# CM_WKUP register map
Vendor: Texas Instruments
Peripheral module from a debugger description file (folder am437x).
Registers are 32-bit, access per field, no defined reset value unless marked. A register's access mark holds for its fields unless they carry their own. Offsets are as the file gives them; lines under a group give offsets from that group; [hi:lo] are bit positions; {n}, {i} and the like mark numbered series; 'fields as' and 'values as' point back to an identical list; <NAME> marks a mode.

## CM_WKUP
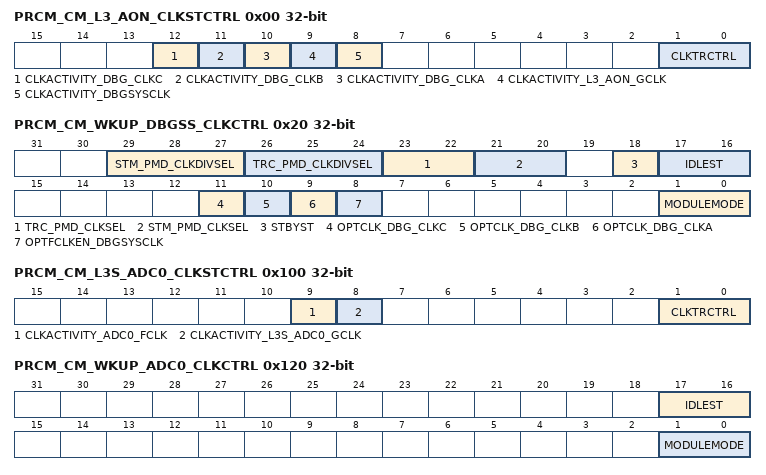
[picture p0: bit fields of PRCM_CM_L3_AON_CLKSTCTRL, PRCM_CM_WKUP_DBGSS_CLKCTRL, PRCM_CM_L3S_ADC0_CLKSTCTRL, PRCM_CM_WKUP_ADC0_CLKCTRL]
0x00 PRCM_CM_L3_AON_CLKSTCTRL — This register enables the domain power state transition. It controls the SW supervised clock domain state transition between ON-ACTIVE and ON-INACTIVE states. It also hold one status bit per clock input of the domain.
  [12] CLKACTIVITY_DBG_CLKC ro — This field indicates the state of the Debugss CLKC clock in the domain.
  [11] CLKACTIVITY_DBG_CLKB ro — This field indicates the state of the Debugss CLKB clock in the domain.
  [10] CLKACTIVITY_DBG_CLKA ro — This field indicates the state of the Debugss CLKA clock in the domain.
  [9] CLKACTIVITY_L3_AON_GCLK ro — This field indicates the state of the L3_AON clock in the domain.
    1=en_2_0x1 (Corresponding clock is active); 0=en_1_0x0 (Corresponding clock is gated)
  [8] CLKACTIVITY_DBGSYSCLK ro — This field indicates the state of the Debugss sysclk clock in the domain.
    values as CLKACTIVITY_L3_AON_GCLK
  [1:0] CLKTRCTRL rw — Controls the clock state transition of the l3 AON clock domain.
    3=en_4_0x3 (Reserved); 2=en_3_0x2 (SW_WKUP: Start a software forced wake-up transition on the domain.); 1=en_2_0x1 (SW_SLEEP: Start a software forced sleep transition on the domain.); 0=en_1_0x0 (NO_SLEEP: Sleep transition cannot be initiated. Wakeup transition may however occur.)
0x20 PRCM_CM_WKUP_DBGSS_CLKCTRL — This register manages the DEBUGSS clocks. [warm reset insensitive]
  [29:27] STM_PMD_CLKDIVSEL rw — STM Trace clock divider control
    4=en_3_0x4 (Divide by 4); 2=en_2_0x2 (Divide by 2); 0=en_1_0x0 (Divide by 1)
  [26:24] TRC_PMD_CLKDIVSEL rw — TPIU trace clock divider control
    values as STM_PMD_CLKDIVSEL
  [23:22] TRC_PMD_CLKSEL rw — TPIU Trace clock select
    3=en_4_0x3 (Selects CLKC as TPIU trace clock); 2=en_3_0x2 (Selects CLKB as TPIU trace clock); 1=en_2_0x1 (Selects CLKA as TPIU trace clock); 0=en_1_0x0 (Selects DGBSYSCLK as TPIU trace clock)
  [21:20] STM_PMD_CLKSEL rw — STM trace clock select
    3=en_4_0x3 (Selects CLKC as STM trace clock); 2=en_3_0x2 (Selects CLKB as STM trace clock); 1=en_2_0x1 (Selects CLKA as STM trace clock); 0=en_1_0x0 (Selects DGBSYSCLK as STM trace clock)
  [18] STBYST ro — Module standby status.
    1=en_2_0x1 (Module is in standby); 0=en_1_0x0 (Module is functional (not in standby))
  [17:16] IDLEST ro — Module idle status.
    3=en_4_0x3 (Module is disabled and cannot be accessed); 2=en_3_0x2 (Module is in Idle mode (only OCP part). It is functional if using separate functional clock); 1=en_2_0x1 (Module is performing transition: wakeup, or sleep, or sleep abortion); 0=en_1_0x0 (Module is fully functional, including OCP)
  [11] OPTCLK_DBG_CLKC rw — Controls Optional Functional Clock CLKC
    1=en_2_0x1 (Enable optional clock DEBUG_CLKC); 0=en_1_0x0 (Disable optional clock DEBUG_CLKC)
  [10] OPTCLK_DBG_CLKB rw — Controls Optional Functional Clock CLKB
    1=en_2_0x1 (Enable optional clock DEBUG_CLKB); 0=en_1_0x0 (Disable optional clock DEBUG_CLKB)
  [9] OPTCLK_DBG_CLKA rw — Optional functional clock control
    1=en_2_0x1 (Enable optional clock DEBUG_CLKA); 0=en_1_0x0 (Disable optional clock DEBUG_CLKA)
  [8] OPTFCLKEN_DBGSYSCLK rw — Optional functional clock control.
    1=en_2_0x1 (Optional functional clock is enabled); 0=en_1_0x0 (Optional functional clock is disabled)
  [1:0] MODULEMODE rw — Control the way mandatory clocks are managed.
    3=en_4_0x3 (Reserved); 2=en_3_0x2 (Module is explicitly enabled. Interface clock (if not used for functions) may be gated according to the clock domain state. Functional clocks are guarantied to stay present. As long as in this configuration, power domain sleep transition cannot happen.); 1=en_2_0x1 (Reserved); 0=en_1_0x0 (Module is disable by SW. Any OCP access to module results in an error, except if resulting from a module wakeup (asynchronous wakeup).)
0x100 PRCM_CM_L3S_ADC0_CLKSTCTRL — This register enables the domain power state transition. It controls the SW supervised clock domain state transition between ON-ACTIVE and ON-INACTIVE states. It also hold one status bit per clock input of the domain.
  [9] CLKACTIVITY_ADC0_FCLK ro — This field indicates the state of the ADC0 FCLK clock in the domain.
    values as PRCM_CM_L3_AON_CLKSTCTRL.CLKACTIVITY_L3_AON_GCLK
  [8] CLKACTIVITY_L3S_ADC0_GCLK ro — This field indicates the state of the L3S_ADC0 clock in the domain.
    values as PRCM_CM_L3_AON_CLKSTCTRL.CLKACTIVITY_L3_AON_GCLK
  [1:0] CLKTRCTRL rw — Controls the clock state transition of the always on clock domain.
    values as PRCM_CM_L3_AON_CLKSTCTRL.CLKTRCTRL
0x120 PRCM_CM_WKUP_ADC0_CLKCTRL — This register manages the ADC0 clocks.
  [17:16] IDLEST ro — Module idle status.
    values as PRCM_CM_WKUP_DBGSS_CLKCTRL.IDLEST
  [1:0] MODULEMODE rw — Control the way mandatory clocks are managed.
    values as PRCM_CM_WKUP_DBGSS_CLKCTRL.MODULEMODE
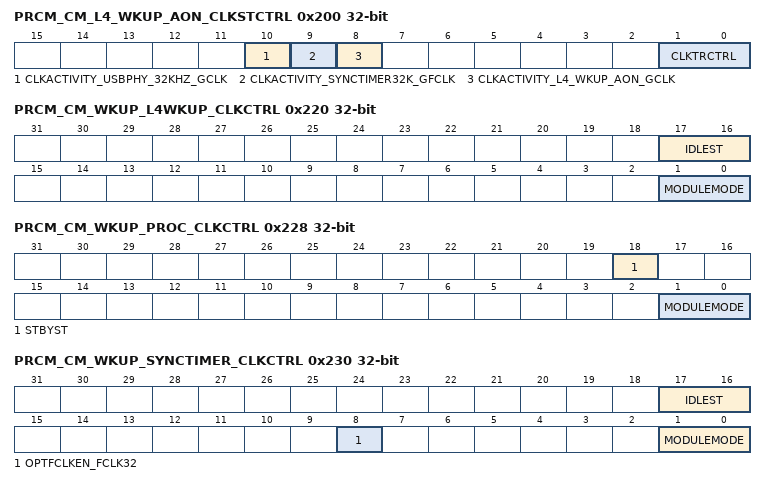
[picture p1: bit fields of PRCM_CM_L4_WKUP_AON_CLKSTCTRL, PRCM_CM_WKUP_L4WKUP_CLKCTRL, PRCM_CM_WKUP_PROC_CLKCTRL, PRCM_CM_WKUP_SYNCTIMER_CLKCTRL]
0x200 PRCM_CM_L4_WKUP_AON_CLKSTCTRL ro — This register enables the domain power state transition. It controls the SW supervised clock domain state transition between ON-ACTIVE and ON-INACTIVE states. It also hold one status bit per clock input of the domain.
  [10] CLKACTIVITY_USBPHY_32KHZ_GCLK — This field indicates the state of the USBPHY 32KHZ clock in the domain.
    values as PRCM_CM_L3_AON_CLKSTCTRL.CLKACTIVITY_L3_AON_GCLK
  [9] CLKACTIVITY_SYNCTIMER32K_GFCLK — This field indicates the state of the SYNCTIMER clock in the domain.
    values as PRCM_CM_L3_AON_CLKSTCTRL.CLKACTIVITY_L3_AON_GCLK
  [8] CLKACTIVITY_L4_WKUP_AON_GCLK — This field indicates the state of the L4_WKUP clock in the domain.
    values as PRCM_CM_L3_AON_CLKSTCTRL.CLKACTIVITY_L3_AON_GCLK
  [1:0] CLKTRCTRL — Controls the clock state transition of the always on L4 clock domain.
0x220 PRCM_CM_WKUP_L4WKUP_CLKCTRL ro — This register manages the L4WKUP clocks.
  [17:16] IDLEST — Module idle status.
    values as PRCM_CM_WKUP_DBGSS_CLKCTRL.IDLEST
  [1:0] MODULEMODE — Control the way mandatory clocks are managed.
0x228 PRCM_CM_WKUP_PROC_CLKCTRL ro — This register manages the WKUP M3 clocks.
  [18] STBYST — Module standby status.
    values as PRCM_CM_WKUP_DBGSS_CLKCTRL.STBYST
  [1:0] MODULEMODE — Control the way mandatory clocks are managed.
0x230 PRCM_CM_WKUP_SYNCTIMER_CLKCTRL — This register manages the SYNCTIMER clocks.
  [17:16] IDLEST ro — Module idle status.
    values as PRCM_CM_WKUP_DBGSS_CLKCTRL.IDLEST
  [8] OPTFCLKEN_FCLK32 rw — Optional functional clock control.
    values as PRCM_CM_WKUP_DBGSS_CLKCTRL.OPTFCLKEN_DBGSYSCLK
  [1:0] MODULEMODE rw — Control the way mandatory clocks are managed.
    values as PRCM_CM_WKUP_DBGSS_CLKCTRL.MODULEMODE
0x238 PRCM_CM_WKUP_CLKDIV32K_CLKCTRL — This register manages the CLKDIV32K clocks.
  [8] OPTFCLKEN_FCLK rw — Optional functional clock control.
    values as PRCM_CM_WKUP_DBGSS_CLKCTRL.OPTFCLKEN_DBGSYSCLK
0x240 PRCM_CM_WKUP_USBPHY0_CLKCTRL — This register manages the USBPHY0 32KHz clocks.
  [8] OPTFCLKEN_CLK32K rw — Optional functional clock control.
    values as PRCM_CM_WKUP_DBGSS_CLKCTRL.OPTFCLKEN_DBGSYSCLK
0x248 PRCM_CM_WKUP_USBPHY1_CLKCTRL — This register manages the USBPHY1 32KHz clocks.
  fields as PRCM_CM_WKUP_USBPHY0_CLKCTRL
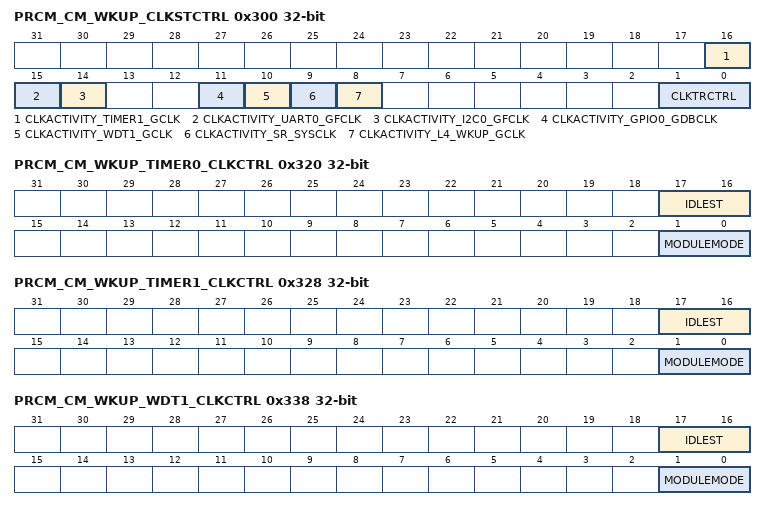
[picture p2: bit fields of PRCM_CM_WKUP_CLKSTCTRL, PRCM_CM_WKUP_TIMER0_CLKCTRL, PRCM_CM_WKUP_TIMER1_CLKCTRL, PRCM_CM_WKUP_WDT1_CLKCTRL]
0x300 PRCM_CM_WKUP_CLKSTCTRL — This register enables the domain power state transition. It controls the SW supervised clock domain state transition between ON-ACTIVE and ON-INACTIVE states. It also hold one status bit per clock input of the domain.
  [16] CLKACTIVITY_TIMER1_GCLK ro — This field indicates the state of the TIMER1 clock in the domain.
    values as PRCM_CM_L3_AON_CLKSTCTRL.CLKACTIVITY_L3_AON_GCLK
  [15] CLKACTIVITY_UART0_GFCLK ro — This field indicates the state of the UART0 clock in the domain.
    values as PRCM_CM_L3_AON_CLKSTCTRL.CLKACTIVITY_L3_AON_GCLK
  [14] CLKACTIVITY_I2C0_GFCLK ro — This field indicates the state of the I2C0 clock in the domain.
    values as PRCM_CM_L3_AON_CLKSTCTRL.CLKACTIVITY_L3_AON_GCLK
  [11] CLKACTIVITY_GPIO0_GDBCLK ro — This field indicates the state of the WKUPGPIO_DBGICLK clock in the domain.
    values as PRCM_CM_L3_AON_CLKSTCTRL.CLKACTIVITY_L3_AON_GCLK
  [10] CLKACTIVITY_WDT1_GCLK ro — This field indicates the state of the WDT1_GCLK clock in the domain.
    values as PRCM_CM_L3_AON_CLKSTCTRL.CLKACTIVITY_L3_AON_GCLK
  [9] CLKACTIVITY_SR_SYSCLK ro — This field indicates the state of the SMARTREFLEX SYSCLK clock in the domain.
    values as PRCM_CM_L3_AON_CLKSTCTRL.CLKACTIVITY_L3_AON_GCLK
  [8] CLKACTIVITY_L4_WKUP_GCLK ro — This field indicates the state of the L4_WKUP clock in the domain.
    values as PRCM_CM_L3_AON_CLKSTCTRL.CLKACTIVITY_L3_AON_GCLK
  [1:0] CLKTRCTRL rw — Controls the clock state transition of the always on clock domain.
    values as PRCM_CM_L3_AON_CLKSTCTRL.CLKTRCTRL
0x320 PRCM_CM_WKUP_TIMER0_CLKCTRL — This register manages the TIMER0 clocks.
  fields as PRCM_CM_WKUP_ADC0_CLKCTRL
0x328 PRCM_CM_WKUP_TIMER1_CLKCTRL — This register manages the TIMER1 clocks.
  fields as PRCM_CM_WKUP_ADC0_CLKCTRL
0x338 PRCM_CM_WKUP_WDT1_CLKCTRL — This register manages the WDT1 clocks.
  fields as PRCM_CM_WKUP_ADC0_CLKCTRL
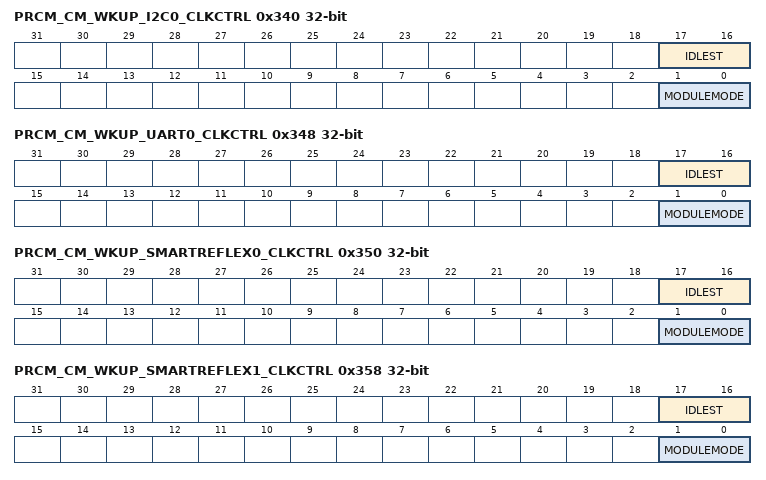
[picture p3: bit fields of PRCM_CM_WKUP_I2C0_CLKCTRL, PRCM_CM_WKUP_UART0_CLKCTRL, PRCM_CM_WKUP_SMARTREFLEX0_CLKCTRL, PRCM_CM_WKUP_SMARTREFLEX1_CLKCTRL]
0x340 PRCM_CM_WKUP_I2C0_CLKCTRL — This register manages the I2C0 clocks.
  fields as PRCM_CM_WKUP_ADC0_CLKCTRL
0x348 PRCM_CM_WKUP_UART0_CLKCTRL — This register manages the UART0 clocks.
  fields as PRCM_CM_WKUP_ADC0_CLKCTRL
0x350 PRCM_CM_WKUP_SMARTREFLEX0_CLKCTRL — This register manages the SmartReflex0 clocks.
  fields as PRCM_CM_WKUP_ADC0_CLKCTRL
0x358 PRCM_CM_WKUP_SMARTREFLEX1_CLKCTRL — This register manages the SmartReflex1 clocks.
  fields as PRCM_CM_WKUP_ADC0_CLKCTRL
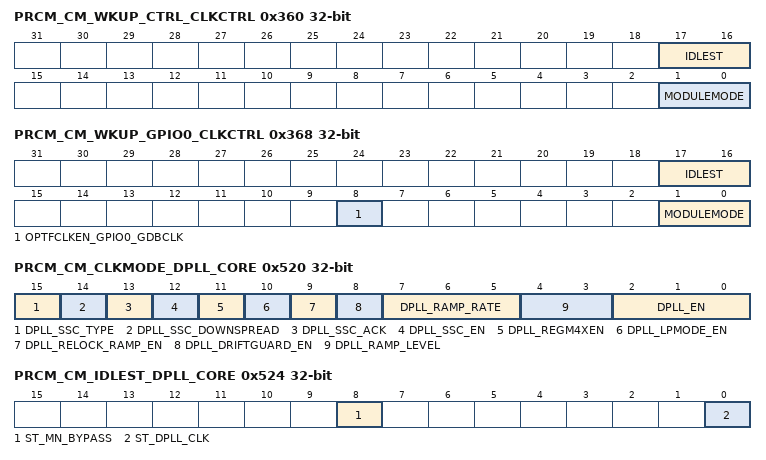
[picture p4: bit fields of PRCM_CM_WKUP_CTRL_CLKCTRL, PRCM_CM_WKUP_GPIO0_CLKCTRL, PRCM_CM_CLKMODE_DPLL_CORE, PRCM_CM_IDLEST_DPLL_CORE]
0x360 PRCM_CM_WKUP_CTRL_CLKCTRL — This register manages the Control Module clocks.
  fields as PRCM_CM_WKUP_ADC0_CLKCTRL
0x368 PRCM_CM_WKUP_GPIO0_CLKCTRL — This register manages the GPIO0 clocks.
  [17:16] IDLEST ro — Module idle status.
    values as PRCM_CM_WKUP_DBGSS_CLKCTRL.IDLEST
  [8] OPTFCLKEN_GPIO0_GDBCLK rw — Optional functional clock control.
    values as PRCM_CM_WKUP_DBGSS_CLKCTRL.OPTFCLKEN_DBGSYSCLK
  [1:0] MODULEMODE rw — Control the way mandatory clocks are managed.
    values as PRCM_CM_WKUP_DBGSS_CLKCTRL.MODULEMODE
0x520 PRCM_CM_CLKMODE_DPLL_CORE — This register allows controlling the DPLL modes.
  [15] DPLL_SSC_TYPE rw — Select between Triangular and SquareWave Spread Spectrum Clocking
    1=en_2_0x1 (Square Wave Spread Spectrum Clocking is selected (only available under proper licensing agreement)); 0=en_1_0x0 (Triangular Spread Spectrum Clocking is selected)
  [14] DPLL_SSC_DOWNSPREAD rw — Control if only low frequency spread is required
    1=en_2_0x1 (When SSC is enabled, clock frequency is spread only on the lower side of the programmed frequency); 0=en_1_0x0 (When SSC is enabled, clock frequency is spread on both sides of the programmed frequency)
  [13] DPLL_SSC_ACK ro — Acknowledgement from the DPLL regarding start and stop of Spread Spectrum Clocking feature
    1=en_2_0x1 (SSC has been turned on on PLL o/ps); 0=en_1_0x0 (SSC has been turned off on PLL o/ps)
  [12] DPLL_SSC_EN rw — Enable or disable Spread Spectrum Clocking
    1=en_2_0x1 (SSC enabled); 0=en_1_0x0 (SSC disabled)
  [11] DPLL_REGM4XEN ro — Enable the REGM4XEN mode of the DPLL. [[br]]Please check the DPLL documentation to check when this mode can be enabled.
    0=en_1_0x0 (REGM4XEN mode of the DPLL is disabled)
  [10] DPLL_LPMODE_EN rw — Set the DPLL in Low Power mode. [[br]]Check the DPLL documentation to see when this can be enabled.
    1=en_2_0x1 (Low power mode of the DPLL is enabled); 0=en_1_0x0 (Low power mode of the DPLL is disabled)
  [9] DPLL_RELOCK_RAMP_EN rw — If enabled, the clock ramping feature is used applied during the lock process, as well as the relock process. [[br]]If disabled, the clock ramping feature is used only during the first lock.
  [8] DPLL_DRIFTGUARD_EN rw — This bit allows to enable or disable the automatic recalibration feature of the DPLL. [[br]]The DPLL will automatically start a recalibration process upon assertion of the DPLL's RECAL flag if this bit is set.
    1=en_2_0x1 (DRIFTGUARD feature is enabled); 0=en_1_0x0 (DRIFTGUARD feature is disabled)
  [7:5] DPLL_RAMP_RATE rw — Selects the time in terms of DPLL REFCLKs spent at each stage of the clock ramping process
    7=en_8_0x7 (512 REFCLKs); 6=en_7_0x6 (128 REFCLKs); 5=en_6_0x5 (64 REFCLKs); 4=en_5_0x4 (32 REFCLKs); 3=en_4_0x3 (16 REFCLKs); 2=en_3_0x2 (8 REFCLKs); 1=en_2_0x1 (4 REFCLKs); 0=en_1_0x0 (2 REFCLKs)
  [4:3] DPLL_RAMP_LEVEL rw — The DPLL provides an output clock frequency ramping feature when switching from bypass clock to normal clock during lock and re-lock. [[br]]The frequency ramping will happen in a maximum of 4 steps in frequency before the DPLL's frequency lock indicator is asserted. [[br]]This register is used to enable/disable the DPLL ramping feature. [[br]]If enabled, it is also used to select the algorithm used for clock ramping
    3=en_4_0x3 (Reserved); 2=en_3_0x2 (CLKOUT => Bypass clk -> Fout/4 -> Fout/2 -> Fout/1.5 -> Fout CLKOUTX2 => Bypass clk -> Foutx2/4 -> Foutx2/2 -> Foutx2/1.5 -> Foutx2); 1=en_2_0x1 (CLKOUT => Bypass clk -> Fout/8 -> Fout/4 -> Fout/2 -> Fout CLKOUTX2 => Bypass clk -> Foutx2/8 -> Foutx2/4 -> Foutx2/2 -> Foutx2); 0=en_1_0x0 (CLKOUT => No ramping CLKOUTX2 => No ramping)
  [2:0] DPLL_EN rw — DPLL control. [[br]]Upon Warm Reset, the PRCM DPLL control state machine updates this register to reflect MN Bypass mode.
    7=en_8_0x7 (Enables the DPLL in Lock mode); 6=en_7_0x6 (Put the DPLL in Idle Bypass Fast Relock mode.); 5=en_6_0x5 (Put the DPLL in Idle Bypass Low Power mode.); 4=en_5_0x4 (Put the DPLL in MN Bypass mode. The DPLL_MULT register bits are reset to 0 automatically by putting the DPLL in this mode.); {v}=en_{v+1}_{0x0+v} (Reserved) (v=0..3)
0x524 PRCM_CM_IDLEST_DPLL_CORE ro — This register allows monitoring the master clock activity. This register is read only and automatically updated. [warm reset insensitive]
  [8] ST_MN_BYPASS — DPLL MN_BYPASS status
    1=en_2_0x1 (DPLL is in MN_Bypass); 0=en_1_0x0 (DPLL is not in MN_Bypass)
  [0] ST_DPLL_CLK — DPLL clock activity
    1=en_2_0x1 (DPLL is LOCKED); 0=en_1_0x0 (DPLL is either in bypass mode or in stop mode.)
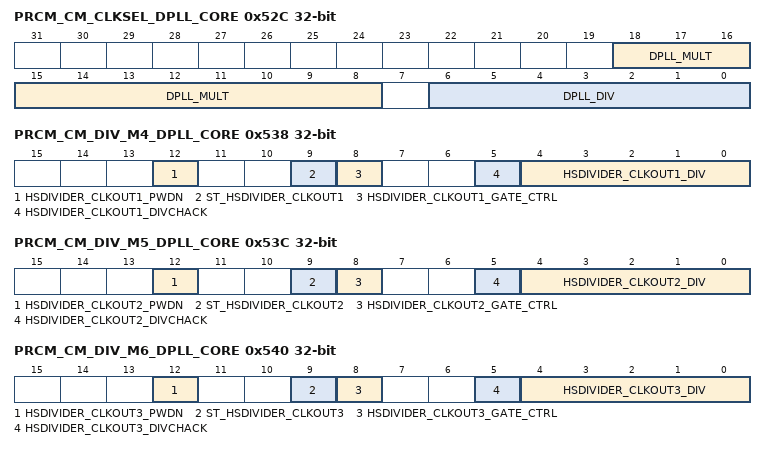
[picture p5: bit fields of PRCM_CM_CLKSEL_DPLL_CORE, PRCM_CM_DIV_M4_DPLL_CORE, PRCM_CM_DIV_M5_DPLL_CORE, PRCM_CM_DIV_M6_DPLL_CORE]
0x52C PRCM_CM_CLKSEL_DPLL_CORE — This register provides controls over the DPLL.
  [18:8] DPLL_MULT rw — DPLL multiplier factor (2 to 2047). [[br]]This register is automatically cleared to 0 when the DPLL_EN field in the *CLKMODE_DPLL* register is set to select MN Bypass mode. [[br]](equal to input M of DPLL[[br]] M=2 to [[br]]2047 => DPLL multiplies by M)
    1=en_2_0x1 (Reserved); 0=en_1_0x0 (Reserved)
  [6:0] DPLL_DIV rw — DPLL divider factor (0 to 127) (equal to input N of DPLL[[br]] actual division factor is N+1).
0x538 PRCM_CM_DIV_M4_DPLL_CORE — This register provides controls over the CLKOUT1 o/p of the HSDIVIDER.
  [12] HSDIVIDER_CLKOUT1_PWDN rw — Power down for HSDIVIDER M4 divider and hence CLKOUT1 output
    1=en_2_0x1 (M4 divider is powered down); 0=en_1_0x0 (M4 divider active)
  [9] ST_HSDIVIDER_CLKOUT1 ro — HSDIVIDER CLKOUT1 status
    1=en_2_0x1 (The clock output is enabled); 0=en_1_0x0 (The clock output is gated)
  [8] HSDIVIDER_CLKOUT1_GATE_CTRL rw — Control gating of HSDIVIDER CLKOUT1
    1=en_2_0x1 (Force this clock to stay enabled even if there is no request); 0=en_1_0x0 (Automatically gate this clock when there is no dependency for it)
  [5] HSDIVIDER_CLKOUT1_DIVCHACK ro — Toggle on this status bit after changing HSDIVIDER_CLKOUT1_DIV indicates that the change in divider value has taken effect
  [4:0] HSDIVIDER_CLKOUT1_DIV rw — DPLL post-divider factor, M4, for internal clock generation. [[br]]Divide values from 1 to 31.
    0=en_1_0x0 (Reserved)
0x53C PRCM_CM_DIV_M5_DPLL_CORE — This register provides controls over the CLKOUT2 o/p of the HSDIVIDER.
  [12] HSDIVIDER_CLKOUT2_PWDN rw — PPower down for HSDIVIDER M5 divider and hence CLKOUT2 output
    1=en_2_0x1 (M5 divider is powered down); 0=en_1_0x0 (M5 divider is ACTIVE)
  [9] ST_HSDIVIDER_CLKOUT2 ro — HSDIVIDER CLKOUT2 status
    values as PRCM_CM_DIV_M4_DPLL_CORE.ST_HSDIVIDER_CLKOUT1
  [8] HSDIVIDER_CLKOUT2_GATE_CTRL rw — Control gating of HSDIVIDER CLKOUT2
    values as PRCM_CM_DIV_M4_DPLL_CORE.HSDIVIDER_CLKOUT1_GATE_CTRL
  [5] HSDIVIDER_CLKOUT2_DIVCHACK ro — Toggle on this status bit after changing HSDIVIDER_CLKOUT2_DIV indicates that the change in divider value has taken effect
  [4:0] HSDIVIDER_CLKOUT2_DIV rw — DPLL post-divider factor, M5, for internal clock generation. [[br]]Divide values from 1 to 31.
    0=en_1_0x0 (Reserved)
0x540 PRCM_CM_DIV_M6_DPLL_CORE — This register provides controls over the CLKOUT3 o/p of the HSDIVIDER.
  [12] HSDIVIDER_CLKOUT3_PWDN rw — Power down for HSDIVIDER M6 divider and hence CLKOUT3 output
    1=en_2_0x1 (M6 divider is powered down); 0=en_1_0x0 (M6 divider is ACTIVE)
  [9] ST_HSDIVIDER_CLKOUT3 ro — HSDIVIDER CLKOUT3 status
    values as PRCM_CM_DIV_M4_DPLL_CORE.ST_HSDIVIDER_CLKOUT1
  [8] HSDIVIDER_CLKOUT3_GATE_CTRL rw — Control gating of HSDIVIDER CLKOUT3
    values as PRCM_CM_DIV_M4_DPLL_CORE.HSDIVIDER_CLKOUT1_GATE_CTRL
  [5] HSDIVIDER_CLKOUT3_DIVCHACK ro — Toggle on this status bit after changing HSDIVIDER_CLKOUT3_DIV indicates that the change in divider value has taken effect
  [4:0] HSDIVIDER_CLKOUT3_DIV rw — DPLL post-divider factor, M6, for internal clock generation. [[br]]Divide values from 1 to 31.
    0=en_1_0x0 (Reserved)
0x548 PRCM_CM_SSC_DELTAMSTEP_DPLL_CORE — Control the DeltaMStep parameter for Spread Spectrum Clocking technique DeltaMStep is split into fractional and integer part. [warm reset insensitive]
  [19:0] DELTAMSTEP rw — Fractional setting for DeltaMStep parameter
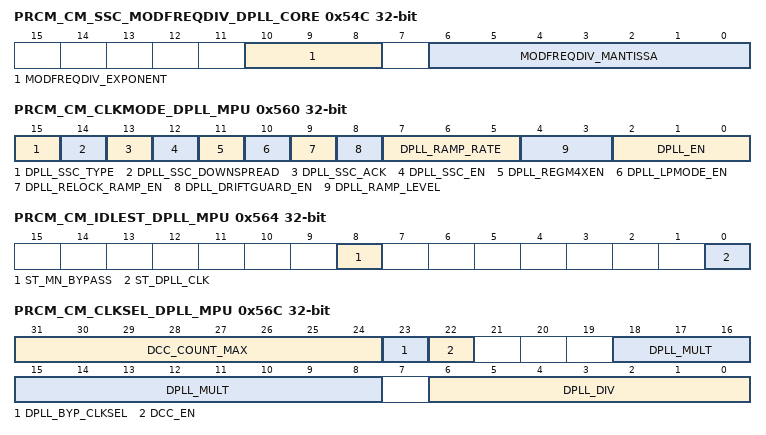
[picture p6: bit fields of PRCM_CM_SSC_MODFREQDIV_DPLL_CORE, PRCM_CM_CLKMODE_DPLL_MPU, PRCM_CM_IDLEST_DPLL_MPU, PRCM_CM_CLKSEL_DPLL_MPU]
0x54C PRCM_CM_SSC_MODFREQDIV_DPLL_CORE — Control the Modulation Frequency (Fm) for Spread Spectrum Clocking technique by defining it as a ratio of DPLL_REFCLK/4 Fm = [DPLL_REFCLK/4]/MODFREQDIV MODFREQDIV = MODFREQDIV_MANTISSA * 2^MODFREQDIV_EXPONENT [warm reset insensitive]
  [10:8] MODFREQDIV_EXPONENT rw — Set the Exponent component of MODFREQDIV factor
  [6:0] MODFREQDIV_MANTISSA rw — Set the Mantissa component of MODFREQDIV factor
0x560 PRCM_CM_CLKMODE_DPLL_MPU — This register allows controlling the DPLL modes.
  fields as PRCM_CM_CLKMODE_DPLL_CORE
0x564 PRCM_CM_IDLEST_DPLL_MPU ro — This register allows monitoring the master clock activity. This register is read only and automatically updated.[warm reset insensitive]
  fields as PRCM_CM_IDLEST_DPLL_CORE
0x56C PRCM_CM_CLKSEL_DPLL_MPU — This register provides controls over the DPLL.
  [31:24] DCC_COUNT_MAX rw — The value "NbCycles" set in this field determines the duration of the clock ramp step during which output frequency is Fdpll/(2*M2). [[br]]The duration is computed as 32 x NbCycles of WKUP-L4 clock cycles (SYSCLK/~26MHz). [[br]]Duration should be > 1.5us to allow enough time for DCC to lock. [[br]]This bit-field is only relevant when DCC_EN=1.
  [23] DPLL_BYP_CLKSEL rw — Selects CLKINP or CLKINPULOW as Bypass Clock
    1=en_2_0x1 (Selects CLKINPULOW as Bypass Clock); 0=en_1_0x0 (Selects CLKINP Clock as BYPASS Clock)
  [22] DCC_EN rw — Enable or disable Duty Cycle Correction. [[br]]Must be enabled only for frequency > 1GHz. [[br]]When enabled, the CLKOUTHIF output of the DPLL is used after duty cycle correction instead of CLKOUT. [[br]]M3 divider is hard-wired to 1 so the lock frequency Fdpll is directly provided to MPU.
    1=en_2_0x1 (DCC enabled); 0=en_1_0x0 (DCC disabled)
  [18:8] DPLL_MULT rw — DPLL multiplier factor (2 to 2047). [[br]]This register is automatically cleared to 0 when the DPLL_EN field in the *CLKMODE_DPLL* register is set to select MN Bypass mode. [[br]](equal to input M of DPLL[[br]] M=2 to [[br]]2047 => DPLL multiplies by M).
    1=en_2_0x1 (1 : Reserved); 0=en_1_0x0 (0 : Reserved)
  [6:0] DPLL_DIV rw — DPLL divider factor (0 to 127) (equal to input N of DPLL[[br]] actual division factor is N+1).
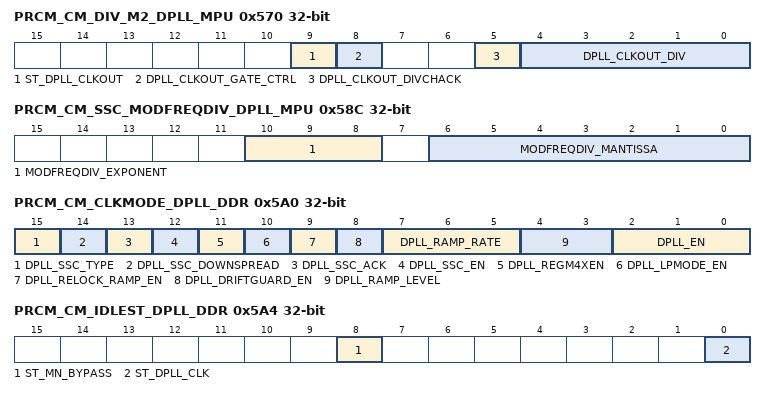
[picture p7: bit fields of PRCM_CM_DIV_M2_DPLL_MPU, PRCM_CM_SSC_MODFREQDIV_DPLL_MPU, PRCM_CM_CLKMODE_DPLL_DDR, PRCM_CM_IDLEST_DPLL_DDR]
0x570 PRCM_CM_DIV_M2_DPLL_MPU — This register provides controls over the M2 divider of the DPLL.
  [9] ST_DPLL_CLKOUT ro — DPLL CLKOUT status
    values as PRCM_CM_DIV_M4_DPLL_CORE.ST_HSDIVIDER_CLKOUT1
  [8] DPLL_CLKOUT_GATE_CTRL rw — Control gating of DPLL CLKOUT
    values as PRCM_CM_DIV_M4_DPLL_CORE.HSDIVIDER_CLKOUT1_GATE_CTRL
  [5] DPLL_CLKOUT_DIVCHACK ro — Toggle on this status bit after changing DPLL_CLKOUT_DIV indicates that the change in divider value has taken effect
  [4:0] DPLL_CLKOUT_DIV rw — DPLL M2 post-divider factor (1 to 31).
    0=en_1_0x0 (Reserved)
0x588 PRCM_CM_SSC_DELTAMSTEP_DPLL_MPU — Control the DeltaMStep parameter for Spread Spectrum Clocking technique DeltaMStep is split into fractional and integer part. [warm reset insensitive]
  [19:0] DELTAMSTEP rw — Fractional setting for DeltaMStep parameter
0x58C PRCM_CM_SSC_MODFREQDIV_DPLL_MPU — Control the Modulation Frequency (Fm) for Spread Spectrum Clocking technique by defining it as a ratio of DPLL_REFCLK/4 Fm = [DPLL_REFCLK/4]/MODFREQDIV MODFREQDIV = MODFREQDIV_MANTISSA * 2^MODFREQDIV_EXPONENT [warm reset insensitive]
  fields as PRCM_CM_SSC_MODFREQDIV_DPLL_CORE
0x5A0 PRCM_CM_CLKMODE_DPLL_DDR — This register allows controlling the DPLL modes.
  fields as PRCM_CM_CLKMODE_DPLL_CORE
0x5A4 PRCM_CM_IDLEST_DPLL_DDR ro — This register allows monitoring the master clock activity. This register is read only and automatically updated. [warm reset insensitive]
  fields as PRCM_CM_IDLEST_DPLL_CORE
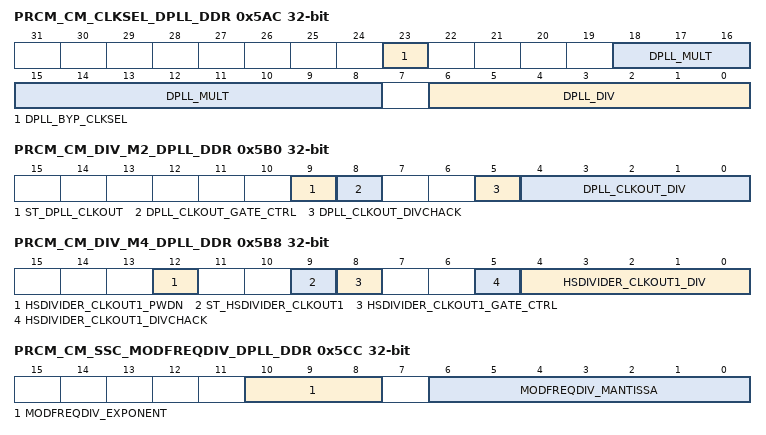
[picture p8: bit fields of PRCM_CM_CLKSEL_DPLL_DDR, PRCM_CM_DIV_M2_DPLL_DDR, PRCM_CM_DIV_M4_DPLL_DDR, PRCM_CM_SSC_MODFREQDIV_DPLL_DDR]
0x5AC PRCM_CM_CLKSEL_DPLL_DDR — This register provides controls over the DPLL.
  [23] DPLL_BYP_CLKSEL rw — Select CLKINP orr CLKINPULOW as bypass clock
    values as PRCM_CM_CLKSEL_DPLL_MPU.DPLL_BYP_CLKSEL
  [18:8] DPLL_MULT rw — DPLL multiplier factor (2 to 2047). [[br]]This register is automatically cleared to 0 when the DPLL_EN field in the *CLKMODE_DPLL* register is set to select MN Bypass mode. [[br]](equal to input M of DPLL[[br]] M=2 to [[br]]2047 => DPLL multiplies by M).
    1=en_2_0x1 (1 : Reserved); 0=en_1_0x0 (0 : Reserved)
  [6:0] DPLL_DIV rw — DPLL divider factor (0 to 127) (equal to input N of DPLL[[br]] actual division factor is N+1).
0x5B0 PRCM_CM_DIV_M2_DPLL_DDR — This register provides controls over the M2 divider of the DPLL.
  fields as PRCM_CM_DIV_M2_DPLL_MPU
0x5B8 PRCM_CM_DIV_M4_DPLL_DDR — This register provides controls over the CLKOUT1 o/p of the DDR PLL HSDIVIDER.
  fields as PRCM_CM_DIV_M4_DPLL_CORE
0x5C8 PRCM_CM_SSC_DELTAMSTEP_DPLL_DDR — Control the DeltaMStep parameter for Spread Spectrum Clocking technique DeltaMStep is split into fractional and integer part. [warm reset insensitive]
  [19:0] DELTAMSTEP rw — Fractional setting for DeltaMStep parameter
0x5CC PRCM_CM_SSC_MODFREQDIV_DPLL_DDR — Control the Modulation Frequency (Fm) for Spread Spectrum Clocking technique by defining it as a ratio of DPLL_REFCLK/4 Fm = [DPLL_REFCLK/4]/MODFREQDIV MODFREQDIV = MODFREQDIV_MANTISSA * 2^MODFREQDIV_EXPONENT [warm reset insensitive]
  fields as PRCM_CM_SSC_MODFREQDIV_DPLL_CORE
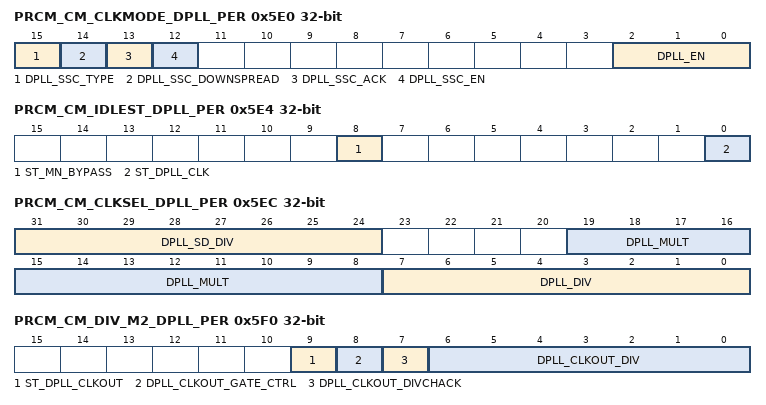
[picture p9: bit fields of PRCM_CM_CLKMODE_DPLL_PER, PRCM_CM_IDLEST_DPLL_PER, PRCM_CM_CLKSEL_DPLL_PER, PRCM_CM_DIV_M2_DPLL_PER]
0x5E0 PRCM_CM_CLKMODE_DPLL_PER — This register allows controlling the DPLL modes.
  [15] DPLL_SSC_TYPE rw — Select between Triangular and SquareWave Spread Spectrum Clocking
    values as PRCM_CM_CLKMODE_DPLL_CORE.DPLL_SSC_TYPE
  [14] DPLL_SSC_DOWNSPREAD rw — Control if only low frequency spread is required
    values as PRCM_CM_CLKMODE_DPLL_CORE.DPLL_SSC_DOWNSPREAD
  [13] DPLL_SSC_ACK ro — Acknowledgement from the DPLL regarding start and stop of Spread Spectrum Clocking feature
    values as PRCM_CM_CLKMODE_DPLL_CORE.DPLL_SSC_ACK
  [12] DPLL_SSC_EN rw — Enable or disable Spread Spectrum Clocking
    1=en_2_0x1 (SSC enabled); 0=en_1_0x0 (SSC disabled)
  [2:0] DPLL_EN rw — DPLL control. [[br]]Upon Warm Reset, the PRCM DPLL control state machine updates this register to reflect DPLL Low Power Stop mode.
    7=en_8_0x7 (Enables the DPLL in Lock mode); 6=en_7_0x6 (Reserved); 5=en_6_0x5 (Put the DPLL in Idle Bypass Low Power mode.); 4=en_5_0x4 (Put the DPLL in MN Bypass mode. The DPLL_MULT register bits are reset to 0 automatically by putting the DPLL in this mode.); 3=en_4_0x3 (Reserved); 2=en_3_0x2 (Reserved2); 1=en_2_0x1 (Reserved); 0=en_1_0x0 (Reserved)
0x5E4 PRCM_CM_IDLEST_DPLL_PER ro — This register allows monitoring the master clock activity. This register is read only and automatically updated. [warm reset insensitive]
  fields as PRCM_CM_IDLEST_DPLL_CORE
0x5EC PRCM_CM_CLKSEL_DPLL_PER — This register provides controls over the DPLL.
  [31:24] DPLL_SD_DIV rw — Sigma-Delta divider select ([[br]]2-255). [[br]]This factor must be set by s/w to ensure optimum jitter performance. [[br]]DPLL_SD_DIV = CEILING ([DPLL_MULT/(DPLL_DIV+1)] * CLKINP / 250), where CLKINP is the input clock of the DPLL in MHz). [[br]]Must be set with M and N factors, and must not be changed once DPLL is locked.
    1=en_2_0x1 (Reserved); 0=en_1_0x0 (Reserved)
  [19:8] DPLL_MULT rw — DPLL multiplier factor (2 to 4095). [[br]]This register is automatically cleared to 0 when the DPLL_EN field in the *CLKMODE_DPLL* register is set to select MN Bypass mode. [[br]](equal to input M of DPLL[[br]] M=2 to [[br]]4095 => DPLL multiplies by M).
    1=en_2_0x1 (1 : Reserved); 0=en_1_0x0 (0 : Reserved)
  [7:0] DPLL_DIV rw — DPLL divider factor (0 to 255) (equal to input N of DPLL[[br]] actual division factor is N+1).
0x5F0 PRCM_CM_DIV_M2_DPLL_PER — This register provides controls over the M2 divider of the DPLL.
  [9] ST_DPLL_CLKOUT ro — DPLL CLKOUT status
    values as PRCM_CM_DIV_M4_DPLL_CORE.ST_HSDIVIDER_CLKOUT1
  [8] DPLL_CLKOUT_GATE_CTRL rw — Control gating of DPLL CLKOUT
    values as PRCM_CM_DIV_M4_DPLL_CORE.HSDIVIDER_CLKOUT1_GATE_CTRL
  [7] DPLL_CLKOUT_DIVCHACK ro — Toggle on this status bit after changing DPLL_CLKOUT_DIV indicates that the change in divider value has taken effect
  [6:0] DPLL_CLKOUT_DIV rw — DPLL M2 post-divider factor (1 to 31).
    0=en_1_0x0 (Reserved)
0x604 PRCM_CM_CLKSEL2_DPLL_PER — This register provides DPLL fractional multiplier factor control and BandWidth Control for PER DPLL.
  [17:0] DPLL_MULT_FRAC rw — DPLL fractional multiplier factor. [[br]]Setting to 0 keeps DPLL in integer mode. [[br]]This field should be used only for DEBUG purpose.
0x608 PRCM_CM_SSC_DELTAMSTEP_DPLL_PER — Control the DeltaMStep parameter for Spread Spectrum Clocking technique DeltaMStep is split into fractional and integer part. [warm reset insensitive]
  [19:0] DELTAMSTEP rw — Fractional setting for DeltaMStep parameter
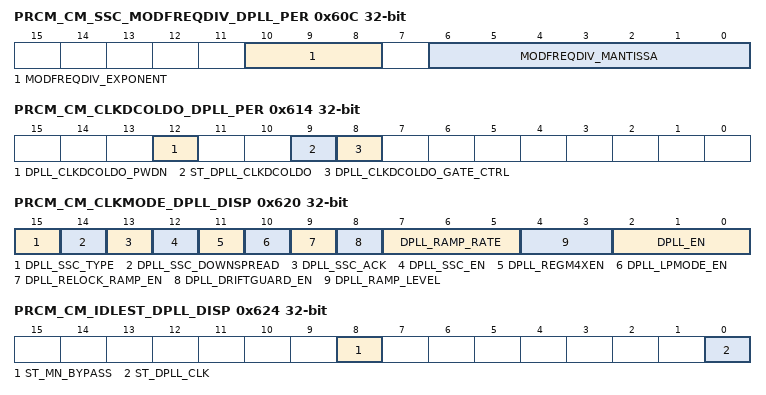
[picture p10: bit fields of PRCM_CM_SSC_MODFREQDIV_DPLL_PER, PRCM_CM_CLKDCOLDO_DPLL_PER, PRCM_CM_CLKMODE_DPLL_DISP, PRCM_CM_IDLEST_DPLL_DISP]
0x60C PRCM_CM_SSC_MODFREQDIV_DPLL_PER — Control the Modulation Frequency (Fm) for Spread Spectrum Clocking technique by defining it as a ratio of DPLL_REFCLK/4 Fm = [DPLL_REFCLK/4]/MODFREQDIV MODFREQDIV = MODFREQDIV_MANTISSA * 2^MODFREQDIV_EXPONENT [warm reset insensitive]
  fields as PRCM_CM_SSC_MODFREQDIV_DPLL_CORE
0x614 PRCM_CM_CLKDCOLDO_DPLL_PER — This register provides controls over the CLKDCOLDO output of the DPLL.
  [12] DPLL_CLKDCOLDO_PWDN rw — Software control for PWRDN on DCOLDO O/P
    1=en_2_0x1 (DCOLDO O/P is PWRDN); 0=en_1_0x0 (DCOLDO O/P is ACTIVE)
  [9] ST_DPLL_CLKDCOLDO ro — DPLL CLKDCOLDO status
    values as PRCM_CM_DIV_M4_DPLL_CORE.ST_HSDIVIDER_CLKOUT1
  [8] DPLL_CLKDCOLDO_GATE_CTRL rw — Control gating of DPLL CLKDCOLDO
    values as PRCM_CM_DIV_M4_DPLL_CORE.HSDIVIDER_CLKOUT1_GATE_CTRL
0x620 PRCM_CM_CLKMODE_DPLL_DISP — This register allows controlling the DPLL modes.
  fields as PRCM_CM_CLKMODE_DPLL_CORE
0x624 PRCM_CM_IDLEST_DPLL_DISP ro — This register allows monitoring the master clock activity. This register is read only and automatically updated. [warm reset insensitive]
  fields as PRCM_CM_IDLEST_DPLL_CORE
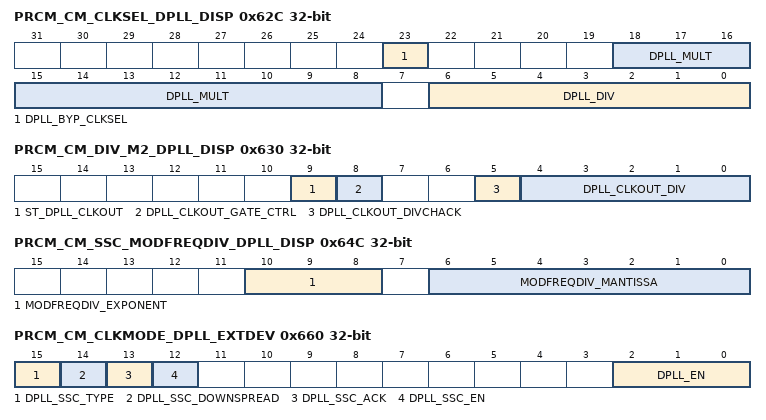
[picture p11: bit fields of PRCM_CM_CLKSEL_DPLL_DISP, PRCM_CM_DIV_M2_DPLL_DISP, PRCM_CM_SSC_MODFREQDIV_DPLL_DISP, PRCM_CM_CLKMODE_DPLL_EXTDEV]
0x62C PRCM_CM_CLKSEL_DPLL_DISP — This register provides controls over the DPLL.
  [23] DPLL_BYP_CLKSEL rw — Select CLKINP or CLKINPULOW as bypass clock
    values as PRCM_CM_CLKSEL_DPLL_MPU.DPLL_BYP_CLKSEL
  [18:8] DPLL_MULT rw — DPLL multiplier factor (2 to 2047). [[br]]This register is automatically cleared to 0 when the DPLL_EN field in the *CLKMODE_DPLL* register is set to select MN Bypass mode. [[br]](equal to input M of DPLL[[br]] M=2 to [[br]]2047 => DPLL multiplies by M).
    1=en_2_0x1 (1 : Reserved); 0=en_1_0x0 (0 : Reserved)
  [6:0] DPLL_DIV rw — DPLL divider factor (0 to 127) (equal to input N of DPLL[[br]] actual division factor is N+1).
0x630 PRCM_CM_DIV_M2_DPLL_DISP — This register provides controls over the M2 divider of the DPLL.
  fields as PRCM_CM_DIV_M2_DPLL_MPU
0x648 PRCM_CM_SSC_DELTAMSTEP_DPLL_DISP — Control the DeltaMStep parameter for Spread Spectrum Clocking technique DeltaMStep is split into fractional and integer part. [warm reset insensitive]
  [19:0] DELTAMSTEP rw — Fractional setting for DeltaMStep parameter
0x64C PRCM_CM_SSC_MODFREQDIV_DPLL_DISP — Control the Modulation Frequency (Fm) for Spread Spectrum Clocking technique by defining it as a ratio of DPLL_REFCLK/4 Fm = [DPLL_REFCLK/4]/MODFREQDIV MODFREQDIV = MODFREQDIV_MANTISSA * 2^MODFREQDIV_EXPONENT [warm reset insensitive]
  fields as PRCM_CM_SSC_MODFREQDIV_DPLL_CORE
0x660 PRCM_CM_CLKMODE_DPLL_EXTDEV — This register allows controlling the DPLL modes.
  fields as PRCM_CM_CLKMODE_DPLL_PER
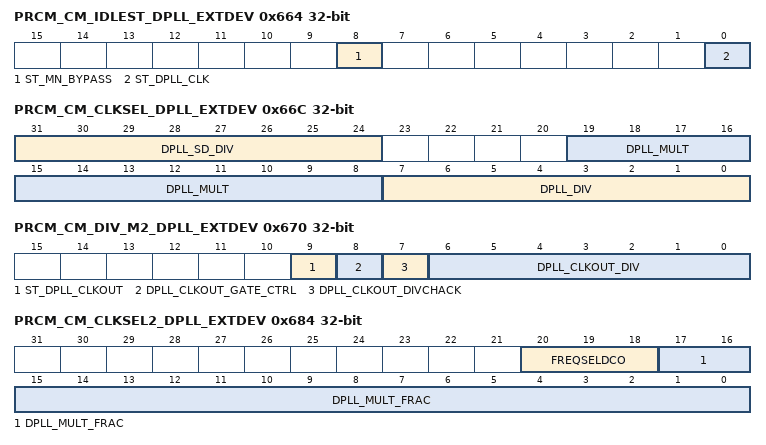
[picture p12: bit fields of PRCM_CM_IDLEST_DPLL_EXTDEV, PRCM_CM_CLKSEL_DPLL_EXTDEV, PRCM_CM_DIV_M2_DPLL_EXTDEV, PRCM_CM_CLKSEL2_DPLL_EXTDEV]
0x664 PRCM_CM_IDLEST_DPLL_EXTDEV ro — This register allows monitoring the master clock activity. This register is read only and automatically updated. [warm reset insensitive]
  fields as PRCM_CM_IDLEST_DPLL_CORE
0x66C PRCM_CM_CLKSEL_DPLL_EXTDEV — This register provides controls over the DPLL.
  fields as PRCM_CM_CLKSEL_DPLL_PER
0x670 PRCM_CM_DIV_M2_DPLL_EXTDEV — This register provides controls over the M2 divider of the DPLL.
  fields as PRCM_CM_DIV_M2_DPLL_PER
0x684 PRCM_CM_CLKSEL2_DPLL_EXTDEV — This register provides DPLL fractional multiplier factor control, SELFREQDCO control and BandWidth Control for EXTDEV DPLL.
  [20:18] FREQSELDCO rw — Register for controlling the input 'freqseldco' for the DPLL_EXTDEV. [[br]]Legal values are '010'[if DCO clk is in the range [[br]]500-1000MHz] and '100'[if DCO clk is in the range [[br]]1000-2000MHz]
    7=en_8_0x7 (RESERVED); 6=en_7_0x6 (RESERVED); 5=en_6_0x5 (RESERVED); 4=en_5_0x4 (This values needs to be selected in the DCO clk freq is in the range 1000-2000 MHz.); 3=en_4_0x3 (Reserved); 2=en_3_0x2 (This values needs to be selected in the DCO clk freq is in the range 500-1000 MHz.); 1=en_2_0x1 (Reserved); 0=en_1_0x0 (Reserved)
  [17:0] DPLL_MULT_FRAC rw — DPLL fractional multiplier factor. [[br]]Setting to 0 keeps DPLL in integer mode.
0x688 PRCM_CM_SSC_DELTAMSTEP_DPLL_EXTDEV — Control the DeltaMStep parameter for Spread Spectrum Clocking technique DeltaMStep is split into fractional and integer part. [warm reset insensitive]
  [19:0] DELTAMSTEP rw — Fractional setting for DeltaMStep parameter
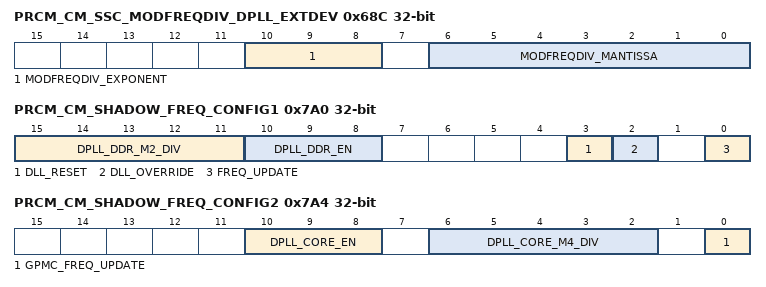
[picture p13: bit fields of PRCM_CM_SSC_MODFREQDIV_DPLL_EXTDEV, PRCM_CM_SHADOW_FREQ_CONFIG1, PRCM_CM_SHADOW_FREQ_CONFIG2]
0x68C PRCM_CM_SSC_MODFREQDIV_DPLL_EXTDEV — Control the Modulation Frequency (Fm) for Spread Spectrum Clocking technique by defining it as a ratio of DPLL_REFCLK/4 Fm = [DPLL_REFCLK/4]/MODFREQDIV MODFREQDIV = MODFREQDIV_MANTISSA * 2^MODFREQDIV_EXPONENT [warm reset insensitive]
  fields as PRCM_CM_SSC_MODFREQDIV_DPLL_CORE
0x7A0 PRCM_CM_SHADOW_FREQ_CONFIG1 — Shadow register to program new DPLL configuration affecting EMIF and GPMC (L3 clock) functional frequency during DVFS. The PRCM h/w automatically applies the new configuration after EMIF/GPMC have been put in idle state.
  [15:11] DPLL_DDR_M2_DIV rw — Shadow register for CM_DIV_M2_DPLL_DDR.DPLL_CLKOUT_DIV. [[br]]The main register is loaded by WKUP-M3 with the shadow register value after EMIF IDLE if the FREQ_UPDATE field is set to '1'. [[br]]Divide value from 1 to 31.
    0=en_1_0x0 (Reserved)
  [10:8] DPLL_DDR_EN rw — Shadow register for CM_CLKMODE_DPLL_DDR.DPLL_EN. [[br]]The main register is loaded by WKUP-M3 with the shadow register value after EMIF IDLE if the FREQ_UPDATE field is set to '1'.
    values as PRCM_CM_CLKMODE_DPLL_CORE.DPLL_EN
  [3] DLL_RESET rw — Specify if DLL should be reset or not during the frequency change hardware sequence.
    1=en_2_0x1 (DLL is reset automatically during the frequency change hardware sequence); 0=en_1_0x0 (DLL is not reset during the frequency change hardware sequence)
  [2] DLL_OVERRIDE rw — Shadow register for CM_DLL_CTRL.DLL_OVERRIDE.The main register is automatically loaded with the shadow register value after EMIF IDLE if the FREQ_UPDATE field is set to '1'.
    1=en_2_0x1 (Lock output is overriden to '1' and code output is overriden with a value coming from control module.); 0=en_1_0x0 (Lock and code outputs are not overriden)
  [0] FREQ_UPDATE rw — Writing '1' indicates that a new configuration is available. [[br]]It is automatically cleared by h/w after the configuration has been applied.
0x7A4 PRCM_CM_SHADOW_FREQ_CONFIG2 — Shadow register to program new DPLL configuration affecting GPMC (L3 clock) functional frequency during DVFS. The PRCM h/w automatically applies the new configuration after EMIF/GPMC have been put in idle state.
  [10:8] DPLL_CORE_EN rw — Shadow register for CM_CLKMODE_DPLL_CORE.DPLL_EN.
    values as PRCM_CM_CLKMODE_DPLL_CORE.DPLL_EN
  [6:2] DPLL_CORE_M4_DIV rw — Shadow register for CM_DIV_M4_DPLL_CORE.DIV. [[br]]The main register is loaded by WKUP-M3 with the shadow register value after GPMC IDLE if the CM_SHADOW_FREQ_CONFIG1.FREQ_UPDATE field is set to '1' and GPMC_FREQ_UPDATE is set to '1'. [[br]]Divide value from 1 to 31.
    0=en_1_0x0 (Reserved)
  [0] GPMC_FREQ_UPDATE rw — Controls whether or not GPMC has to be put automatically into idle during the frequency change operation.
    1=en_2_0x1 (GPMC is put automatically into idle during frequency change operation.); 0=en_1_0x0 (GPMC is not put automatically into idle during frequency change operation.)
